# RK3399-AP register map
File version: 1
CPU: CA7 r0p1, little endian, MPU, FPU, I-cache, D-cache, VTOR, 4 interrupt priority bits, 0 interrupts
Registers are 32-bit, read-write, reset 0x0 unless marked. A register's access mark holds for its fields unless they carry their own. Offsets are from the block's base; [hi:lo] are bit positions; 'fields as' and 'values as' point back to an identical list.

## EMMCCORE (part 2 of 2)
Base 0xFE330000
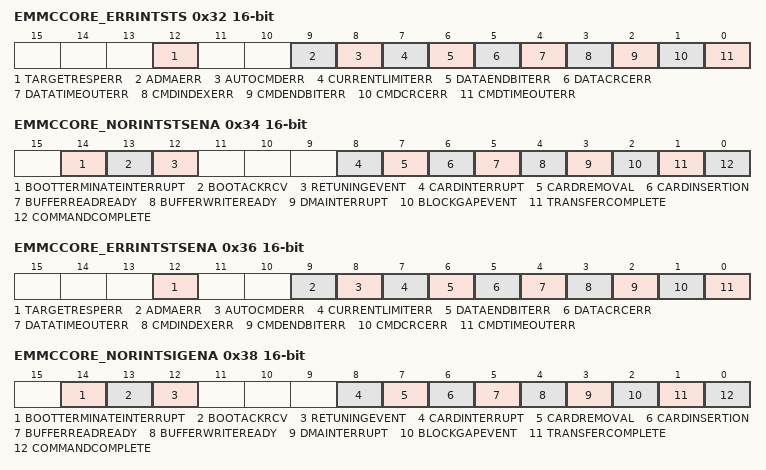
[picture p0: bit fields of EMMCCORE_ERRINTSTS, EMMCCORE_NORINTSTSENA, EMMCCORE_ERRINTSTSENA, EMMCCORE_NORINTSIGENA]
0x32 EMMCCORE_ERRINTSTS 16-bit — Error interrupt status register
  [12] TARGETRESPERR write-1-clears — 0: no error 1: error Occurs when detecting ERROR in m_hresp(dma transaction)
  [9] ADMAERR write-1-clears — 1: Error 0: No error This bit is set when the Host Controller detects errors during ADMA based data transfer. The state of the ADMA at an error occurrence is saved in the ADMA Error Status Register.
  [8] AUTOCMDERR write-1-clears — 0: No Error 1: Error Auto CMD12 and Auto CMD23 use this error status. This bit is set when detecting that one of the bits D00-D04 in Auto CMD Error Status register has changed from 0 to 1. In case of Auto CMD12, this bit is set to 1, not only when the errors in Auto CMD12 occur but also when Auto CMD12 is not executed due to the previous command error.
  [7] CURRENTLIMITERR write-1-clears — 0: No Error 1: Power Fail By setting the SD Bus Power bit in the Power Control Register, the HC is requested to supply power for the SD Bus. If the HC supports the Current Limit Function, it can be protected from an Illegal card by stopping power supply to the card in which case this bit indicates a failure status. Reading 1 means the HC is not supplying power to SD card due to some failure. Reading 0 means that the HC is supplying power and no error has occurred. This bit shall always set to be 0, if the HC does not support this function. Note: The current_Limit_Error is to be implemented if customer application requires it.. By default it is not implementedas there is no specific requirement from Customers.
  [6] DATAENDBITERR write-1-clears — 0: No Error 1: Error Occurs when detecting 0 at the end bit position of read data which uses the DAT line or the end bit position of the CRC status.
  [5] DATACRCERR write-1-clears — 0: No Error 1: Error Occurs when detecting CRC error when transferring read data which uses the DAT line or when detecting the Write CRC Status having a value of other than "010".
  [4] DATATIMEOUTERR write-1-clears — 0: No Error 1: Timeout Occurs when detecting one of following timeout conditions. a. Busy Timeout for R1b, R5b type. b. Busy Timeout after Write CRC status c. Write CRC status Timeout d. Read Data Timeout
  [3] CMDINDEXERR write-1-clears — 0: No Error 1: Error Occurs if a Command Index error occurs in the Command Response.
  [2] CMDENDBITERR — 0: No Error 1: End Bit Error Generated Occurs when detecting that the end bit of a command response is 0.
  [1] CMDCRCERR write-1-clears — 0: No Error 1: CRC Error Generated Command CRC Error is generated in two cases. a. If a response is returned and the Command Time-out Error is set to 0, this bit is set to 1 when detecting a CRT error in the command response b. The HC detects a CMD line conflict by monitoring the CMD line when a command is issued. If the HC drives the CMD line to 1 level, but detects 0 level on the CMD line at the next SDCLK edge, then the HC shall abort the command (Stop driving CMD line) and set this bit to 1. The Command Timeout Error shall also be set to 1 to distinguish CMD line conflict.
  [0] CMDTIMEOUTERR write-1-clears — 0: No Error 1: Timeout Occurs only if the no response is returned within 64 SDCLK cycles from the end bit of the command. If the HC detects a CMD line conflict, in which case Command CRC Error shall also be set. This bit shall be set without waiting for 64 SDCLK cycles because the command will be aborted by the HC.
0x34 EMMCCORE_NORINTSTSENA 16-bit — Normal interrupt status enable register
  [14] BOOTTERMINATEINTERRUPT — 0: Masked 1: Enabled
  [13] BOOTACKRCV — 0: Masked 1: Enabled
  [12] RETUNINGEVENT — 0: Masked 1: Enabled
  [8] CARDINTERRUPT — 0: Masked 1: Enabled
  [7] CARDREMOVAL — 0: Masked 1: Enabled
  [6] CARDINSERTION — 0: Masked 1: Enabled
  [5] BUFFERREADREADY — 0: Masked 1: Enabled
  [4] BUFFERWRITEREADY — 0: Masked 1: Enabled
  [3] DMAINTERRUPT — 0: Masked 1: Enabled
  [2] BLOCKGAPEVENT — 0: Masked 1: Enabled
  [1] TRANSFERCOMPLETE — 0: Masked 1: Enabled
  [0] COMMANDCOMPLETE — 0: Masked 1: Enabled
0x36 EMMCCORE_ERRINTSTSENA 16-bit — Error interrupt status enable register
  [12] TARGETRESPERR — 0: Masked 1: Enabled
  [9] ADMAERR — 0: Masked 1: Enabled
  [8] AUTOCMDERR — 0: Masked 1: Enabled
  [7] CURRENTLIMITERR — 0: Masked 1: Enabled
  [6] DATAENDBITERR — 0: Masked 1: Enabled
  [5] DATACRCERR — 0: Masked 1: Enabled
  [4] DATATIMEOUTERR — 0: Masked 1: Enabled
  [3] CMDINDEXERR — 0: Masked 1: Enabled
  [2] CMDENDBITERR — 0: Masked 1: Enabled
  [1] CMDCRCERR — 0: Masked 1: Enabled
  [0] CMDTIMEOUTERR — 0: Masked 1: Enabled
0x38 EMMCCORE_NORINTSIGENA 16-bit — Normal interrupt signal enable register
  fields as EMMCCORE_NORINTSTSENA
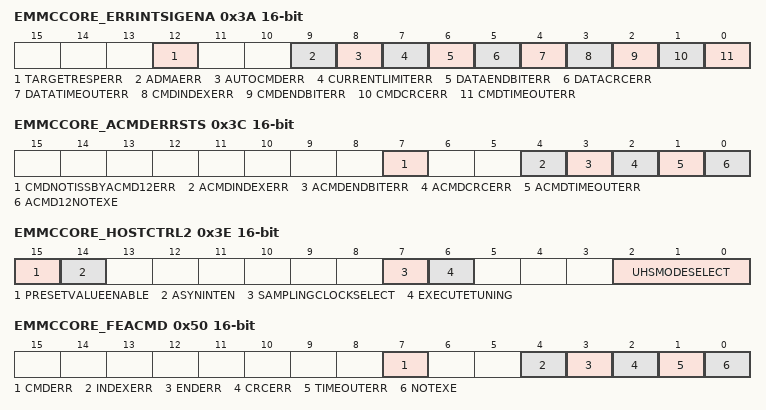
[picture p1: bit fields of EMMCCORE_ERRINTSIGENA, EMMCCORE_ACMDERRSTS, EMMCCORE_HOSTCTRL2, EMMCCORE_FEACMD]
0x3A EMMCCORE_ERRINTSIGENA 16-bit — Error interrupt signal enable register
  fields as EMMCCORE_ERRINTSTSENA
0x3C EMMCCORE_ACMDERRSTS 16-bit ro — Auto CMD error status register
  [7] CMDNOTISSBYACMD12ERR — Command Not Issued By Auto CMD12 Error. Setting this bit to 1 means CMD_wo_DAT is not executed due to an Auto CMD12 error (D04 - D01) in this register. This bit is set to 0 when Auto CMD Error is generated by Auto CMD23. 0: No Error 1: Not Issued
  [4] ACMDINDEXERR — Auto CMD Index Error. Occurs if the Command Index error occurs in response to a command. 0: No Error 1: Error
  [3] ACMDENDBITERR — Auto CMD End Bit Error. Occurs when detecting that the end bit of command response is 0. 0: No Error 1: End Bit Error Generated
  [2] ACMDCRCERR — Auto CMD CRC Error Occurs when detecting a CRC error in the command response. 0: No Error 1: CRC Error Generated
  [1] ACMDTIMEOUTERR — Auto CMD Timeout Error Occurs if the no response is returned within 64 SDCLK cycles from the end bit of the command. If this bit is set to 1, the other error status bits (D04 - D02) are meaningless. 0: No Error 1: Timeout
  [0] ACMD12NOTEXE — Auto CMD12 not Executed If memory multiple block data transfer is not started due to command error, this bit is not set because it is not necessary to issue Auto CMD12. Setting this bit to 1 means the HC cannot issue Auto CMD12 to stop memory multiple block transfer due to some error. If this bit isset to 1, other error status bits (D04 - D01) are meaningless. This bit is set to 0 when Auto CMD Error is generated by Auto CMD23. 0: Executed 1: Not Executed
0x3E EMMCCORE_HOSTCTRL2 16-bit access per field — Host Control 2 Register
  [15] PRESETVALUEENABLE rw — 1: Automatic Selection by Preset Value are Enabled 0: SDCLK and Driver Strength are controlled by Host Driver As the operating SDCLK frequency and I/O driver strength depend on the Host System implementation, it is difficult to determine these parameters in the Standard Host Driver. When Preset Value Enable is set to automatic. This bit enablesthe functions defined in the Preset Value registers. If this bit is set to 0, SDCLK Frequency Select, Clock Generator Select in the Clock Control register and Driver Strength Select in Host Control 2 register are set by Host Driver. If this bit is set to 1, SDCLK Frequency Select, Clock Generator Select in the Clock Control register and Driver Strength Select in Host Control 2 register are set by Host Controller as specified in the Preset Value registers.
  [14] ASYNINTEN rw — Asynchronous Interrupt Enable This bit can be set to 1 if a card support asynchronous interrupt and Asynchronous Interrupt Support is set to 1 in the Capabilities register. Asynchronous interrupt is effective when DAT[1] interrupt is used in 4-bit SD mode(and zero is set to Interrupt Pin Select in the Shared Bus Control register). If this bit is set to 1, the Host Driver can stop the SDCLK during asynchronous interrupt period to save power. During this period, the Host Controller continues to deliver CardInterrupt to the host when it is asserted by the card. 1: Enabled 0: Disabled
  [7] SAMPLINGCLOCKSELECT rw — Sampling Clock Select This bit is set by tuning procedure when Execute Tuning is cleared. Writing 1 to this bit is meaningless and ignored. Setting 1 means that tuning is completed successfully and setting 0 means that tuning is failed. Host Controller uses this bit to select sampling clock to receive CMD and DAT. This bit is cleared by writing 0. Change of this bit is not allowed while the Host Controller is receiving response or a read data block. 1: Tuned clock is used to sample data 0: Fixed clock is used to sample data
  [6] EXECUTETUNING wo write-clears — This bit is set to 1 to start tuning procedure and automatically cleared when tuning procedure is completed. The result of tuning is indicated to Sampling Clock Select. Tuning procedure is aborted by writing 0 for more detail about tuning procedure. 1: Execute Tuning 0: Not Tuned or Tuning Completed
  [2:0] UHSMODESELECT rw — UHS Mode Select. This field is used to select one of UHS-I modes and effective when 1.8V Signaling Enable is set to 1. If Preset Value Enable in the Host Control 2 register is set to 1, Host Controller sets SDCLK Frequency Select, Clock Generator Select in the Clock Control register and Driver Strength Select according to Preset Value registers. In this case, one of preset value registers is selected by this field. Host Driver needs to reset SD Clock Enable before changing this field to avoid generating clock glitch. After setting this field, Host Driver sets SD Clock Enable again. 3\'h0: SDR12 3\'h1: SDR25 3\'h2: SDR50 3\'h3: SDR104 3\'h4: DDR50 3\'h5: HS400 others: Reserved When SDR50, SDR104 or DDR50 is selected for SDIO card, interrupt detection at the block gap shall not be used. Read Wait timing is changed for these modes. Refer to the SDIO Specification Version 3.00 for more detail.
0x50 EMMCCORE_FEACMD 16-bit wo — Force event register for Auto CMD error status
  [7] CMDERR — Force Event for command not issued by Auto CMD12 Error 1: Interrupt is generated 0: No interrupt
  [4] INDEXERR — Force Event for Auto CMD Index Error 1: Interrupt is generated 0: No interrupt
  [3] ENDERR — Force Event for Auto CMD End bit Error 1: Interrupt is generated 0: No interrupt
  [2] CRCERR — Force Event for Auto CMD CRC Error 1: Interrupt is generated 0: No interrupt
  [1] TIMEOUTERR — Force Event for Auto CMD timeout Error 1: Interrupt is generated 0: No interrupt
  [0] NOTEXE — Force Event for Auto CMD12 NOT Executed 1: Interrupt is generated 0: No interrupt
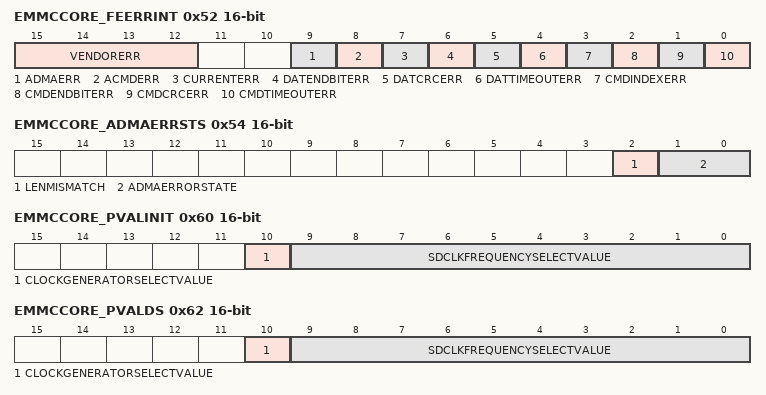
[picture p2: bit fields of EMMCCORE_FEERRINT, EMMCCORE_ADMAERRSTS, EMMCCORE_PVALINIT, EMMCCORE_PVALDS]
0x52 EMMCCORE_FEERRINT 16-bit access per field — Force event register for error interrupt status
  [15:12] VENDORERR ro — Force Event for Vendor Specific Error Status
  [9] ADMAERR wo — Force Event for ADMA Error 1: Interrupt is generated 0: No interrupt
  [8] ACMDERR wo — Force Event for Auto CMD Error 1: Interrupt is generated 0: No interrupt
  [7] CURRENTERR wo — Force Event for Current Limit Error 1: Interrupt is generated 0: No interrupt
  [6] DATENDBITERR wo — Force Event for Data End Bit Error 1: Interrupt is generated 0: No interrupt
  [5] DATCRCERR wo — Force Event for Data CRC Error 1: Interrupt is generated 0: No interrupt
  [4] DATTIMEOUTERR wo — Force Event for Data Timeout Error 1: Interrupt is generated 0: No interrupt
  [3] CMDINDEXERR wo — Force Event for Command Index Error 1: Interrupt is generated 0: No interrupt
  [2] CMDENDBITERR wo — Force Event for Command End Bit Error 1: Interrupt is generated 0: No interrupt
  [1] CMDCRCERR wo — Force Event for Command CRC Error 1: Interrupt is generated 0: No interrupt
  [0] CMDTIMEOUTERR wo — Force Event for Command Timeout Error 1: Interrupt is generated 0: No interrupt
0x54 EMMCCORE_ADMAERRSTS 16-bit ro — ADMA error status register
  [2] LENMISMATCH — ADMA Length Mismatch Error. While Block Count Enable being set, the total data length specified by the Descriptor table is different from that specified by the Block Count and Block Length. Total data length can not be divided by the block length. 1: Error 0: No error
  [1:0] ADMAERRORSTATE — This field indicates the state of ADMA when error is occurred during ADMA data transfer. This field never indicates "10" because ADMA never stops in this state. 0: ST_STOP (Stop DMA) Points to next of the error descriptor 1: ST_FDS (Fetch Descriptor) Points to the error descriptor 2: Never set this state (Not used) 3: ST_TFR (Transfer Data) Points to the next of the error descriptor
0x60 EMMCCORE_PVALINIT 16-bit ro — Preset value register for Initialization
  [10] CLOCKGENERATORSELECTVALUE — This bit is effective when Host Controller supports programmable clockgenerator. 1: Programmable Clock Generator 0: Host Controller Ver2.00 Compatible Clock Generator
  [9:0] SDCLKFREQUENCYSELECTVALUE — 10-bit preset value to set SDCLK Frequency Select in the Clock Control Register is described by a host system.
0x62 EMMCCORE_PVALDS 16-bit ro — Preset value register for Default Speed
  fields as EMMCCORE_PVALINIT
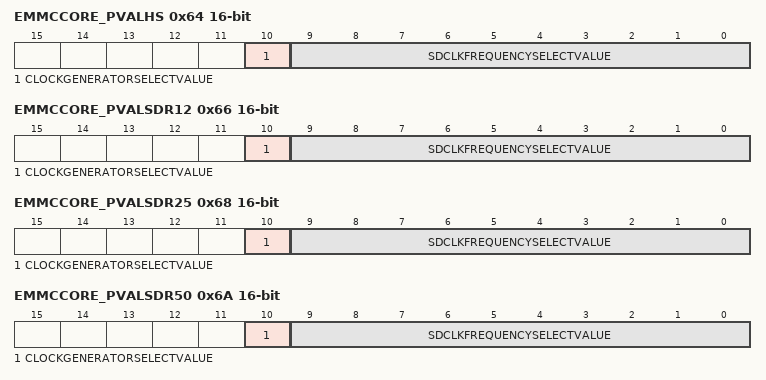
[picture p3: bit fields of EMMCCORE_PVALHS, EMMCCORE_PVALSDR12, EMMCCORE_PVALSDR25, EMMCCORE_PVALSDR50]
0x64 EMMCCORE_PVALHS 16-bit ro — Preset value register for High Speed
  fields as EMMCCORE_PVALINIT
0x66 EMMCCORE_PVALSDR12 16-bit ro — Preset value register for SDR12
  fields as EMMCCORE_PVALINIT
0x68 EMMCCORE_PVALSDR25 16-bit ro — Preset value register for SDR25
  fields as EMMCCORE_PVALINIT
0x6A EMMCCORE_PVALSDR50 16-bit ro — Preset value register for SDR50
  fields as EMMCCORE_PVALINIT
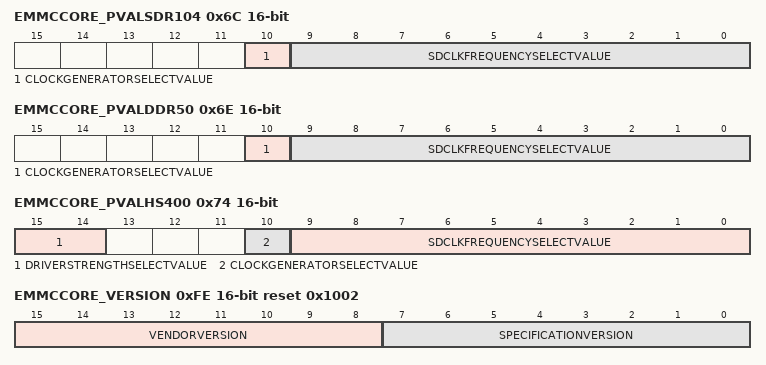
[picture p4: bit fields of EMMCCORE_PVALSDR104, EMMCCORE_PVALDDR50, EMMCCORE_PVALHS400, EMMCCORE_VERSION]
0x6C EMMCCORE_PVALSDR104 16-bit ro — Preset value register for SDR104
  fields as EMMCCORE_PVALINIT
0x6E EMMCCORE_PVALDDR50 16-bit ro — Preset value register for DDR50
  fields as EMMCCORE_PVALINIT
0x70 EMMCCORE_BOOTTIMEOUT — Boot timeout control register
  [31:0] BOOTTIMEOUT — Boot Data Timeout Counter Value This value determines the interval by which DAT line time-outs are detected during boot operation for eMMC card. The value is in number of sd clock.
0x74 EMMCCORE_PVALHS400 16-bit ro — Preset value register for HS400
  [15:14] DRIVERSTRENGTHSELECTVALUE — Driver Strength is supported by 1.8V signaling bus speed modes. This field is meaningless for 3.3V signaling. 2\'b11: Driver Type D is Selected 2\'b10: Driver Type C is Selected 2\'b01: Driver Type A is Selected 2\'b00: Driver Type B is Selected
  [10] CLOCKGENERATORSELECTVALUE — This bit is effective when Host Controller supports programmable clockgenerator. 1: Programmable Clock Generator 0: Host Controller Ver2.00 Compatible Clock Generator
  [9:0] SDCLKFREQUENCYSELECTVALUE — 10-bit preset value to set SDCLK Frequency Select in the Clock Control Register is described by a host system.
0x78 EMMCCORE_VENDOR 16-bit — Vendor register
  [0] ENHANCEDSTROBE — This bit enables the enhanced strobe logic of the Host Controller
0xFC EMMCCORE_SLOTINTSTS 16-bit ro — Slot interrupt status register
  [0] INTSLOT0 — This status bit indicates the OR of Interrupt signal and Wakeup signal for slot
0xFE EMMCCORE_VERSION 16-bit ro reset 0x1002 — Host controller version register
  [15:8] VENDORVERSION — The Vendor Version Number is set to 0x10 (1.0)
  [7:0] SPECIFICATIONVERSION — The Host Controller Version Number is set to 0x02 (SD Host Specification Version 3.00).
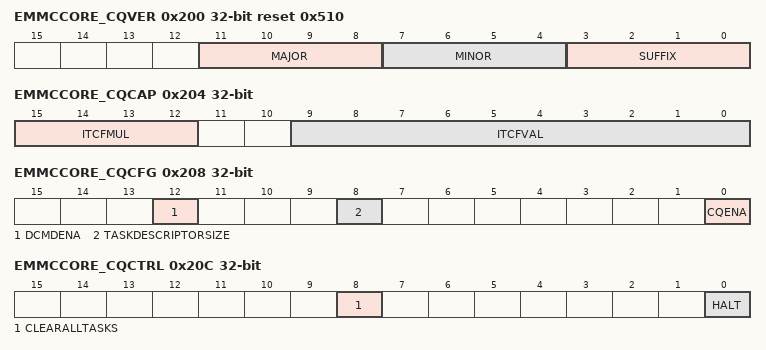
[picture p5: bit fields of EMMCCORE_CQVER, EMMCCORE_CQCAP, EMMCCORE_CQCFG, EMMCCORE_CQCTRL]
0x200 EMMCCORE_CQVER ro reset 0x510 — Command queueing version register
  [11:8] MAJOR — eMMC Major Version Number (digit left of decimal point), in BCD format
  [7:4] MINOR — eMMC Minor Version Number(digit right of decimal point), in BCD format
  [3:0] SUFFIX — eMMC Version Suffix (2nd digit right of decimal point), in BCD format
0x204 EMMCCORE_CQCAP ro — Command queueing capabilities register
  [15:12] ITCFMUL — nternal Timer Clock Frequency Multiplier ITCFMUL and ITCFVAL indicate the frequency of the clock used for interrupt coalescing timer and for determining the SQS polling period. See ITCFVAL definition for details. 4\'h0: 0.001 MHz 4\'h1: 0.01 MHz 4\'h2: 0.1 MHz 4\'h3: 1 MHz 4\'h4: 10 MHz Other values are reserved
  [9:0] ITCFVAL — Internal Timer Clock Frequency Value TCFMUL and ITCFVAL indicate the frequency of the clock used for interrupt coalescing timer and for determining the polling period when using periodic SEND_QUEUE_ STATUS (CMD13) polling. The clock frequency is calculated as ITCFVAL* ITCFMUL. For example, to encode 19.2 MHz, ITCFVAL shall be C0h (= 192 decimal) and ITCFMUL shall be 2h (0.1 MHz) 192 * 0.1 MHz=19.2 MHz
0x208 EMMCCORE_CQCFG — Command queueing configuration register
  [12] DCMDENA — Direct Command (DCMD) Enable This bit indicates to the hardware whether the Task Descriptor in slot #31 of the TDL is a Data Transfer Task Descriptor, or a Direct Command Task Descriptor. CQE uses this bit when a task is issued in slot #31, to determine how to decode the Task Descriptor. 1: Task descriptor in slot #31 is a DCMD Task Descriptor 0: Task descriptor in slot #31 is a Data Transfer Task Descriptor
  [8] TASKDESCRIPTORSIZE — This bit indicates whether the task descriptor size is 128 bits or 64 bits as detailed in Data Structures section. This bit can only be configured when Command Queueing Enable bit is 0 (command queueing is disabled) 1: Task descriptor size is 128 bits 0: Task descriptor size is 64 bits
  [0] CQENA — Command Queueing Enable Software shall write 1 this bit when in order to enable command queueing mode (i.e. enable CQE). When this bit is 0, CQE is disabled and software controls the eMMC bus using the legacy eMMC host controller. Before software writes 1 to this bit, software shall verify that the eMMC host controller is in idle state and there are no commands or data transfers ongoing. When software wants to exit command queueing mode, it shall clear all previous tasks if such exist before setting this bit to 0.
0x20C EMMCCORE_CQCTRL access per field — Command queueing controlregister/Command queueing control register
  [8] CLEARALLTASKS wo write-clears — Software shall write 1 this bit when it wants to clear all the tasks sent to the device. This bit can only be written when CQE is in halt state (i.e. Halt bit is 1). When software writes 1, the value of the register is updated to 1, and CQE shall reset CQTDBR register and all other context information for all unfinished tasks. Then CQE will clear this bit. Software should poll on this bit until it is set to back 0 and may then resume normal operation, by clearing the Halt bit. CQE does not communicate to the device that the tasks were cleared. It is software\'s responsibility to order the device to discard the tasks in its queue using CMDQ_TASK_MGMT command. Writing 0 to this register shall have no effect.
  [0] HALT rw — Host software shall write 1 to the bit when it wants to acquire software control over the eMMC bus and disable CQE from issuing commands on the bus. For example, issuing a Discard Task command (CMDQ_TASK_MGMT). When software writes 1, CQE shall complete the ongoing task if such a task is in progress. Once the task is completed and CQE is in idle state, CQE shall not issue new commands and shall indicate so to software by setting this bit to 1. Software may poll on this bit until it is set to 1, and may only then send commands on the eMMC bus. In order to exit halt state (i.e. resume CQE activity), software shall clear this bit (write 0). Writing 0 when the value is already 0 shall have no effect.
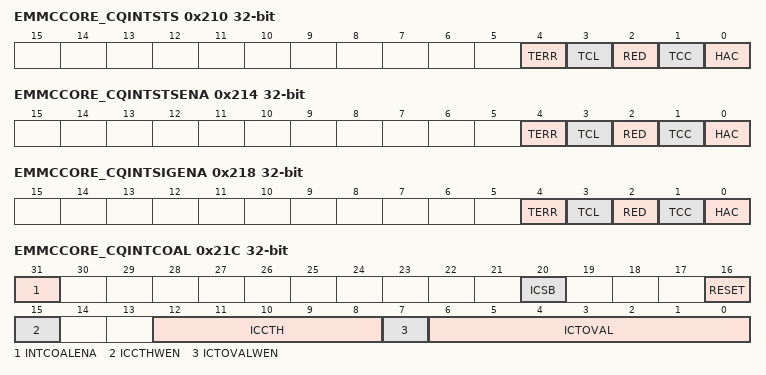
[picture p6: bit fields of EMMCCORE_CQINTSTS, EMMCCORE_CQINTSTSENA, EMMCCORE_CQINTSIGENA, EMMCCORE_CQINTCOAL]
0x210 EMMCCORE_CQINTSTS — Command queueing interruptstatus register/Command queueing interrupt status register
  [4] TERR write-1-clears — Task Error Interrupt This bit is asserted when task error is detected due to invalid task descriptor
  [3] TCL write-1-clears — Task Cleared This status bit is asserted (if CQISTE.TCL=1) when a task clear operation is completed by CQE. The completed task clear operation is either an individual task clear (CQTCLR) or clearing of all tasks (CQCTL).
  [2] RED write-1-clears — Response Error Detected Interrupt This status bit is asserted (if CQISTE.RED=1) when a response is received with an error bit set in the device status field. Software uses CQRMEM register to configure which device status bit fields may trigger an interrupt, and which are masked.
  [1] TCC write-1-clears — Task Complete Interrupt This status bit is asserted(if CQISTE.TCC=1) when at least one of the following two conditions are met: a. A task is completed and the INT bit is set in its Task Descriptor b. Interrupt caused by Interrupt Coalescing logic
  [0] HAC write-1-clears — Halt Complete Interrupt This status bit is asserted (if CQISTE.HAC=1) when halt bit in CQCTL register transitions from 0 to 1 indicating that host controller has completed its current ongoing task and has entered halt state.
0x214 EMMCCORE_CQINTSTSENA — Command queueing interruptstatus enable register/Command queueing interrupt status enable register
  [4] TERR — Task Error Interrupt 1: enable 0: disable
  [3] TCL — Task Cleared 1: enable 0: disable
  [2] RED — Response Error Detected Interrupt 1: enable 0: disable
  [1] TCC — Task Complete Interrupt 1: enable 0: disable
  [0] HAC — Halt Complete Interrupt 1: enable 0: disable
0x218 EMMCCORE_CQINTSIGENA — Command queueing interruptsignal enable register/Command queueing interrupt signal enable register
  fields as EMMCCORE_CQINTSTSENA
0x21C EMMCCORE_CQINTCOAL access per field — Command queueing interruptcoalescing register/Command queueing interrupt coalescing register
  [31] INTCOALENA rw — Interrupt Coalescing Enable/Disable: When set to 0 by software, command responses are neither counted nor timed. Interrupts are still triggered by completion of tasks with INT=1 in the Task Descriptor. When set to 1, the interrupt coalescing mechanism is enabled and coalesced interrupts are generated.
  [20] ICSB ro — Interrupt Coalescing Status Bit : This bit indicates to software whether any tasks (with INT=0) have completed and counted towards interrupt coalescing (i.e., ICSB is set ifand only if IC counter > 0). 1: At least one task completion has been counted (IC counter >0) 0: No task completions have occurred since last counter reset (IC counter =0)
  [16] RESET wo — Counter and Timer Reset(ICCTR): When host driver writes 1, the interrupt coalescing timer and counter are reset
  [15] ICCTHWEN wo — Interrupt Coalescing Counter Threshold Write Enable: When software writes 1, the value ICCTH is updated with the contents written at the same cycle. When software writes 0, the value in ICCTH is not updated. NOTE: Write operations to ICCTH are only allowed when the task queue is empty.
  [12:8] ICCTH rw — Interrupt Coalescing Counter Threshold (ICCTH): Software uses this field to configure the number of task completions (only tasks withINT=0 in the Task Descriptor) which are required in order to generate an interrupt. Counter Operation: As data transfer tasks with INT=0 complete, they are counted byCQE. The counter is reset by software during the interrupt service routine. The counter stops counting when it reaches the value configured in ICCTH. The maximum allowed value is 31 NOTE : When ICCTH is 0, task completions are not counted, and counting-based interrupts are not generated. In order to write to this field, the ICCTHWEN bit must be set at the same write operation.
  [7] ICTOVALWEN wo — Interrupt Coalescing Timeout Value Write Enable: When software writes 1, the value ICTOVAL is updated with the contents written at the same cycle. When software writes 0, the value in ICTOVAL is not updated. NOTE: Write operations to ICTOVAL are only allowed when the task queue is empty.
  [6:0] ICTOVAL rw — Interrupt Coalescing Timeout Value (ICTOVAL): Software uses this field to configure the maximum time allowed between the completion of a task on the bus and the generation of an interrupt. Timer Operation: The timer is reset by software during the interrupt service routine. It starts running when a data transfer task with INT=0 is completed, after the timer was reset. When the timer reaches the value configured in ICTOVAL field it generates an interrupt and stops. The timer\'s unit is equal to 1024 clock periods of the clock whose frequency is specified in the Internal Timer Clock Frequency field CQCAP register. The minimum value is 01h (1024 clock periods) and the maximum value is 7Fh (127*1024 clock periods). For example, a CQCAP field value of 0 indicates a 19.2 MHz clock frequency (period = 52.08 ns). If the setting in ICTOVAL is 10h, the calculated polling period is 16*1024*52.08 ns= 853.33 us. NOTE:When ICTOVAL is 0, the timer is not running, and timer- based interrupts are not generated.In order to write to this field, the ICTOVALWEN bit must be set at the same write operation.
0x220 EMMCCORE_CQTDLBA — Command queueing task descriptor list base address register
  [31:0] TDLBA — Task Descriptor List Base Address This register stores the LSB bits (bits 31:0) of the byte address of the head of the Task Descriptor List in system memory. The size of the task descriptor list is 32 * (Task Descriptor size + Transfer Descriptor size) as configured by Host driver. This address shall be set on Byte1 KByte boundary. The lower 10 bits of this register shall be set to 0 by software and shall be ignored by CQE.
0x224 EMMCCORE_CQTDLBAU — Command queueing task descriptor list base address upper 32bits register
  [31:0] TDLBA — Task Descriptor List Base Address This register stores the MSB bits (bits 63:32) of the byte address of the head of the Task Descriptor List in system memory. The size of the task descriptor list is 32 * (Task Descriptor size + Transfer Descriptor size) as configured by Host driver. This register is reserved when using 32-bit addressing mode.
0x228 EMMCCORE_CQTDB — Command queueing task doorbell register
  [31:0] TASKDOORBELL — Command Queueing Task Doorbell Software shall configure TDLBA and TDLBAU, and enable CQE in CQCFG before using this register. Writing 1 to bit n of this register triggers CQE to start processing the task encoded in slot n of the TDL. CQE always processes tasks in-order according to the order submitted to the list by CQTDBR write transactions. CQE processes Data Transfer tasks by reading the Task Descriptor and sending QUEUED_TASK_PARAMS (CMD44) and QUEUED_TASK_ADDRESS (CMD45) commands to the device. CQE processes DCMD tasks (in slot #31, when enabled) by reading the Task Descriptor, and generating the command encoded by its index and argument. The corresponding bit is cleared to 0 by CQE in one of the following events: a. When a task execution is completed (with success or error) b. The task is cleared using CQTCLR register c. All tasks are cleared using CQCTL register d. CQE is disabled using CQCFG register Software may initiate multiple tasks at the same time (batch submission) by writing 1 to multiple bits of this register in the same transaction. In the case of batch submission: CQE shall process the tasks in order of the task index, starting with the lowest index. If one or more tasks in the batch are marked with QBR, the ordering of execution will be based on said processing order. Writing 0 by software shall have no impact on the hardware, and will not change the value of the register bit.
0x22C EMMCCORE_CQTDBN — Command queueing task doorbell/Command queueing task doorbell notification register
  [31:0] TCN — Task Complete Notification CQE shall set bit n of this register (at the same time it clears bit n of CQTDBR) when a task execution is completed (with success or error). When receiving interrupt for task completion, software may read this register to know which tasks have finished. After reading this register, software may clear the relevant bit fields by writing 1 to the corresponding bits.
0x230 EMMCCORE_CQDQSTS ro — Command queueing device queuestatus register/Command queueing device queue status register
  [31:0] DQS — Device Queue Status Every time the Host controller receives a queue status register (QSR) from the device, it updates this register with the response of status command, i.e. the device\'s queue status.
0x234 EMMCCORE_CQDPT ro — Command queueing devicepending tasks register/Command queueing device pending tasks register
  [31:0] DPT — Device Pending Tasks Bit n of this register is set if and only if QUEUED_TASK_PARAMS (CMD44) and QUEUED_TASK_ADDRESS (CMD45) were sent for this specific task and if this task hasn’t been executed yet. CQE shall set this bit after receiving a successful response for CMD45. CQE shall clear this bit after the task has completed execution. Software needs to read this register in the task-discard procedure, when the controlleris halted, to determine if the task is queued in the device. If the task is queued, the driver sends a CMDQ_TASK_MGMT (CMD48) to the device ordering it to discard the task. Then software clears the task in the CQE. Only then the software orders CQE to resume its operation using CQCTL register.
0x238 EMMCCORE_CQTCLR — Command queueing task clearregister/Command queueing task clear register
  [31:0] CQTC — Command Queueing Task Clear Writing 1 to bit n of this register orders CQE to clear a task which software has previously issued. This bit can only be written when CQE is in Halt state as indicated in CQCFG register Halt bit. When software writes 1 to a bit in this register, CQE updates the value to 1, and starts clearing the data structures related to the task. CQE clears the bit fields (sets a value of 0) in CQTCLR and in CQTDBR once clear operation is complete. Software should poll on the CQTCLR until it is cleared to verify clear operation was complete. Writing to this register only clears the task in the CQE and does not have impact on the device. In order to discard the task in the device, host softwareshall send CMDQ_TASK _MGMT while CQE is still in Halt state. Host driver is not allowed to use this register to clear multiple tasks at the same time. Clearing multiple tasks can be done using CQCTL register. Writing 0 to a register bit shall have no impact.
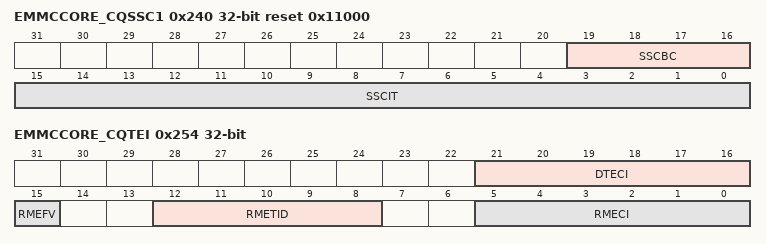
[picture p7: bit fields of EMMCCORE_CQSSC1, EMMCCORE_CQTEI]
0x240 EMMCCORE_CQSSC1 reset 0x11000 — Command queueing send statusconfiguration register 1/Command queueing send status configuration register 1
  [19:16] SSCBC — Send Status Command Block Counter This field indicates to CQE when to send SEND_QUEUE_STATUS (CMD13) command to inquire the status of the device\'s task queue. A value of n means CQE shall send status command on the CMD line, during the transfer of data block BLOCK_CNT-n, on the data lines, where BLOCK_CNT is the number of blocks inthe current transaction. A value of 0 means that SEND_QUEUE_STATUS (CMD13) command shall not be sent during the transaction. Instead it will be sentonly when the data lines are idle. A value of 1 means that STATUS command is to be sent during the last block of the transaction.
  [15:0] SSCIT — Send Status Command Idle Timer This field indicates to CQE the polling period to use when using periodic SEND_QUEUE_STATUS (CMD13) polling. Periodic polling is used when tasks are pending in the device, but no data transfer is in progress. When a SEND_QUEUE_STATUS response indicating that no task is ready for execution, CQE counts the configured time until it issues the next SEND_QUEUE_STATUS. Timer units are clock periods of the clock whose frequency is specified in the Internal Timer Clock Frequency field CQCAP egister. The minimum value is 0001h (1 clock period) and the maximum value is FFFFh (65535 clock periods). Default interval is: 4096 clock periods. For example, a CQCAP field value of 0 indicates a 19.2 MHz clock frequency (period = 52.08 ns). If the setting in CQSST is 1000h, the calculated polling period is 4096*52.08 ns= 213.33 us.
0x244 EMMCCORE_CQSSC2 — Command queueing send statusconfiguration register 2/Command queueing send status configuration register 2
  [15:0] SQRCA — Send Queue RCA This field provides CQE with the contents of the 16-bit RCA field in SEND_QUEUE_ STATUS (CMD13) command. argument. CQE shall copy this field to bits 31:16 of the argument when transmitting SEND_ QUEUE_STATUS (CMD13) command
0x248 EMMCCORE_CQCRDT ro — Command queueing command response for direct-command task register
  [31:0] DCLR — Direct Command Last Response This register contains the response of the command generated by the last direct-command (DCMD) task which was sent. CQE shall update this register when it receives the response for a DCMD task. This register is considered valid only after bit 31 of CQTDBR register is cleared by CQE.
0x250 EMMCCORE_CQRMEM ro reset 0xFDF9A080 — Command queueing responsemode error mask register/Command queueing response mode error mask register
  [31:0] RMEM — Response Mode Error Mask This bit is used as in interrupt mask on the device status filed which is received in R1/R1b responses. Bit Value Description (for any bit i): 1: When a R1/R1b response is received, with bit i in the device status set, a RED interrupt is generated 0: When a R1/R1b response is received, bit i in the device status is ignored The reset value of this register is set to trigger an interrupt on all \'Error\' type bits in the device status. NOTE: Responses to CMD13 (SQS) encode the QSR, so they are ignored by this logic.
0x254 EMMCCORE_CQTEI ro — Command queueing task errorinformation register/Command queueing task error information register
  [21:16] DTECI — Data Transfer Error Command Index This field indicates the index of the command which was executed on the data lines when an error occurred. The index shall be set to EXECUTE_READ_TASK (CMD46) or EXECUTE_WRITE_TASK (CMD47) according to the data direction. The field is updated if a data transfer is in progress when an error is detected by CQE, or indicated by eMMC controller.
  [15] RMEFV — Response Mode Error Fields Valid This bit is updated when an error is detected by CQE, or indicated by eMMC controller. If a command transaction is in progress when the error is detected/indicated, the bit is set to 1. If a no command transaction is in progress when the error is detected/indicated, the bit is cleared to 0.
  [12:8] RMETID — Response Mode Error Task ID This field indicates the ID of the task which was executed on the command line when an error occurred. The field is updated if a command transaction is in progress when an error is detected by CQE, or indicated by eMMC controller.
  [5:0] RMECI — Response Mode Error Command Index This field indicates the index of the command which was executed on the command line when an error occurred. The field is updated if a command transaction is in progress when an error is detected by CQE, or indicated by eMMC controller.
0x258 EMMCCORE_CQCRI ro — Command queueing commandresponse index register/Command queueing command response index register
  [5:0] LCRI — Last Command Response Index This field stores the index of the last received command response. CQE shall update the value every time a command response is received.
0x25C EMMCCORE_CQCRA ro — Command queueing commandresponse argument register/Command queueing command response argument register
  [31:0] LCRA — Last Command Response Argument This field stores the argument of the last received command. CQE shall update the value every time a command response is received.
